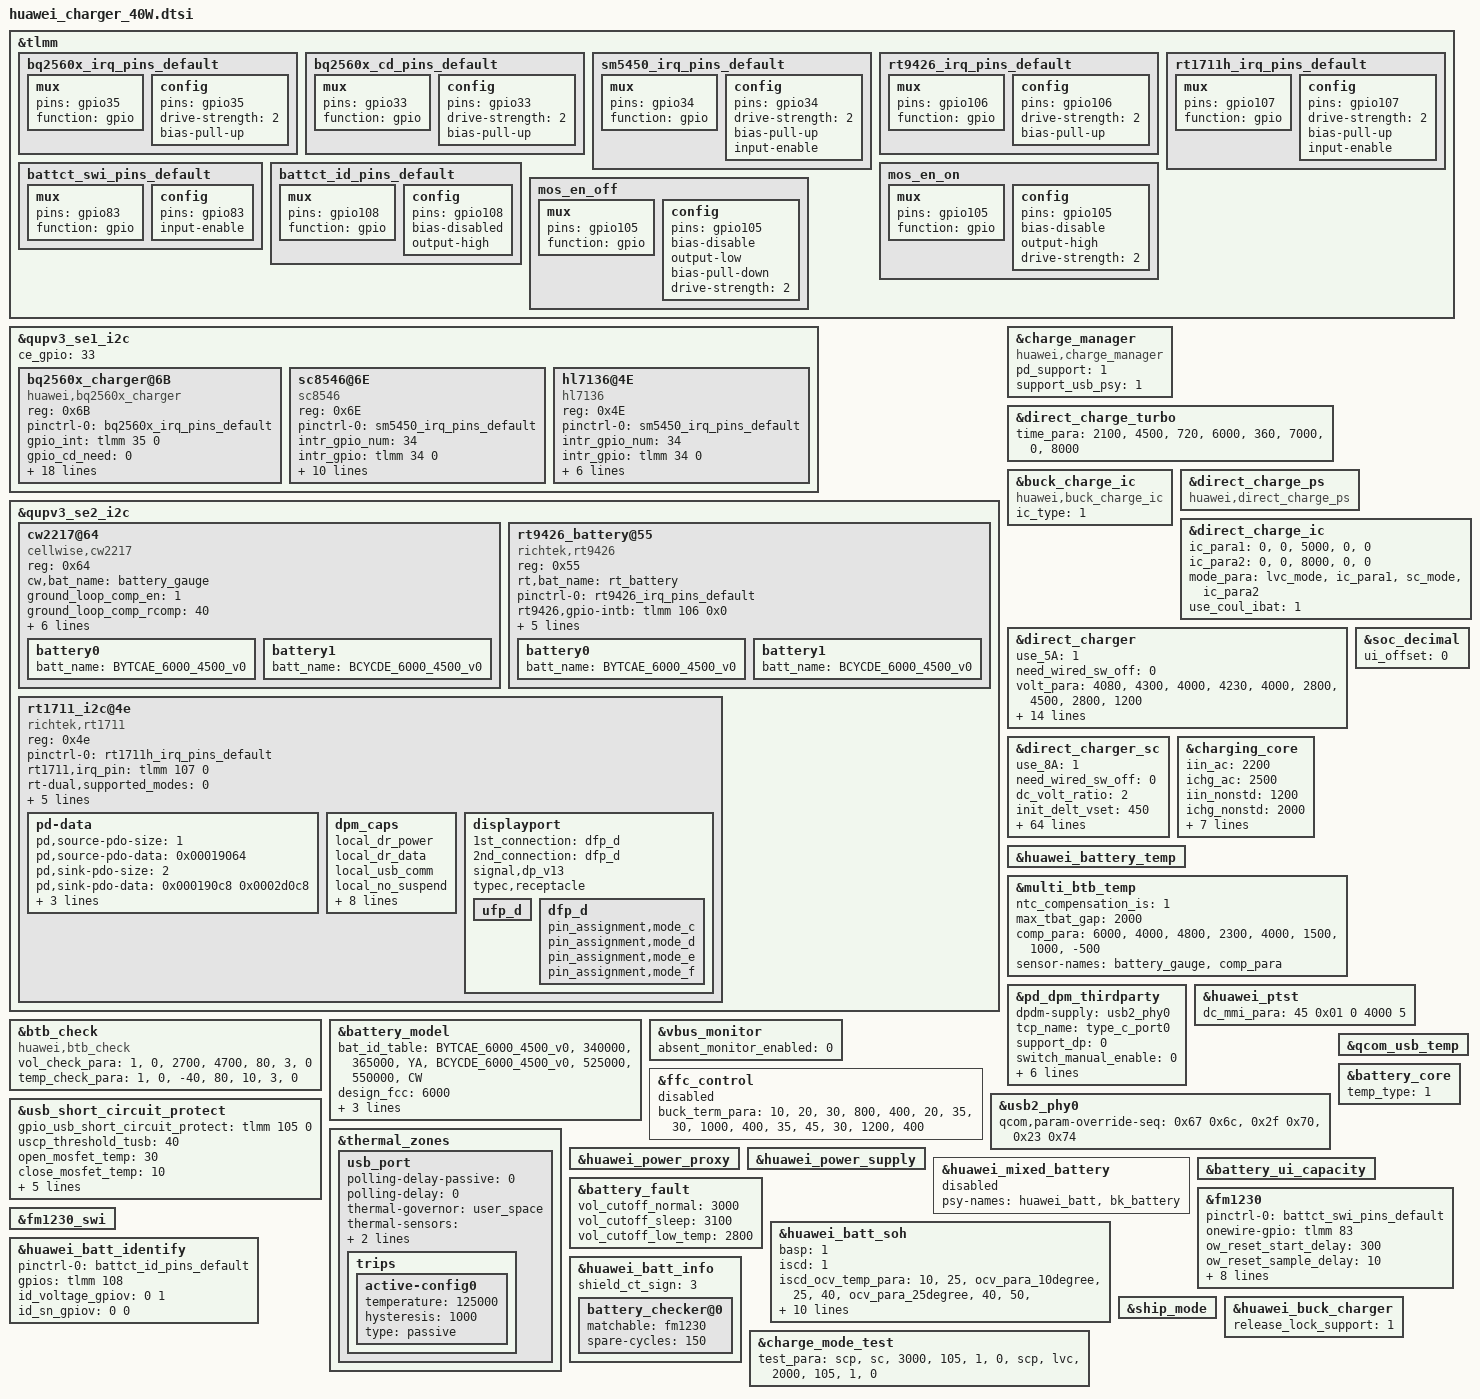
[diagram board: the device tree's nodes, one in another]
&tlmm {
	bq2560x_irq_pins_default: bq2560x_irq_pins_default {
		mux {
			pins = "gpio35";
			function = "gpio";
		};
		config {
			pins = "gpio35";
			drive-strength = <2>;
			bias-pull-up;
		};
	};

	bq2560x_cd_pins_default: bq2560x_cd_pins_default {
		mux {
			pins = "gpio33";
			function = "gpio";
		};
		config {
			pins = "gpio33";
			drive-strength = <2>;
			bias-pull-up;
		};
	};

	sm5450_irq_pins_default: sm5450_irq_pins_default {
		mux {
			pins = "gpio34";
			function = "gpio";
		};
		config {
			pins = "gpio34";
			drive-strength = <2>;
			bias-pull-up;
			input-enable;
		};
	};

	rt9426_irq_pins_default: rt9426_irq_pins_default {
		mux {
			pins = "gpio106";
			function = "gpio";
		};
		config {
			pins = "gpio106";
			drive-strength = <2>;
			bias-pull-up;
		};
	};

	rt1711h_irq_pins_default: rt1711h_irq_pins_default {
		mux {
			pins = "gpio107";
			function = "gpio";
		};
		config {
			pins = "gpio107";
			drive-strength = <2>;
			bias-pull-up;
			input-enable;
		};
	};

	battct_swi_pins_default: battct_swi_pins_default {
		mux {
			pins = "gpio83";
			function = "gpio";
		};
		config {
			pins = "gpio83";
			input-enable;
		};
	};

	battct_id_pins_default: battct_id_pins_default {
		mux {
			pins = "gpio108";
			function = "gpio";
		};
		config {
			pins = "gpio108";
			bias-disabled;
			output-high;
		};
	};

	mos_en_on: mos_en_on {
		mux {
			pins = "gpio105";
			function = "gpio";
		};

		config {
			pins = "gpio105";
			bias-disable;
			output-high;
			drive-strength = <2>; /* 2 MA */
		};
	};

	mos_en_off: mos_en_off {
		mux {
			pins = "gpio105";
			function = "gpio";
		};

		config {
			pins = "gpio105";
			bias-disable;
			output-low;
			bias-pull-down; /* PULL DOWN */
			drive-strength = <2>; /* 2 MA */
		};
	};
};

&qupv3_se1_i2c {
	status = "ok";

	/* auto_key_info @ name: ce_gpio type: uint32 default: 0 */
	ce_gpio = <33>;

	bq2560x_charger@6B{
		compatible = "huawei,bq2560x_charger";
		reg = <0x6B>;
		pinctrl-names = "bq2560x_irq_pins_default";
		pinctrl-0 = <&bq2560x_irq_pins_default>;
		gpio_int = <&tlmm 35 0>;
        gpio_cd_need = <0>;
		bat_comp = <80>;
		vclamp = <224>;
		rilim = <124>;
		adc_channel_iin = <5>;
		adc_channel_vbat_sys = <14>;
		fcp_support = <0>;
		need_check_sgm41511 = <0>;
		hiz_iin_limit = <1>;
		custom_cv = <4496>;
		charge-detect-enable;
		enable_redo_bc12;
		no_need_change_iterm;
		support_sc = <1>;
		ic_role = <1>;
		sc_max_input_current = <1200>;
		sc_max_charge_current  = <2100>;
		disable_batfet_rst_en = <1>; /* if support shipmode, need disable batfet_rst_en */
		shipmode_clear_hiz = <1>;
		status = "ok";
	};

	sc8546@6E {
		compatible = "sc8546";
		reg = <0x6E>;
		pinctrl-names = "default";
		pinctrl-0 = <&sm5450_irq_pins_default>;
		intr_gpio_num = <34>; /* direct defined GPIO num */
		intr_gpio = <&tlmm 34 0>;
		fcp_support = <1>;
		scp_support = <1>;
		sense_r_actual = <20>;
		i2c_recovery = <1>;
		i2c_recovery_addr = <0x6F>;
		switching_frequency = <850>;
		switching_frequency_shift = <1>;
		ic_role = <0>;
		sc_para =
			"default", "8000", "4800",
			"sc8546", "8000", "4800";
		status = "ok";
	};

	hl7136@4E {
		compatible = "hl7136";
		reg = <0x4E>;
		pinctrl-names = "default";
		pinctrl-0 = <&sm5450_irq_pins_default>;
		intr_gpio_num = <34>; /* direct defined GPIO num */
		intr_gpio = <&tlmm 34 0>;
		sense_r_actual = <20>;
		sense_r_config = <50>;
		fcp_support = <1>;
		scp_support = <1>;
		switching_frequency = <500>;
		ic_role = <0>;
		status = "ok";
	};
};

&qupv3_se2_i2c {
	status = "ok";
        cw2217@64 {
		compatible = "cellwise,cw2217";
		reg = <0x64>;
		cw,bat_name = "battery_gauge";
		status = "ok";
		ground_loop_comp_en = <1>;
		ground_loop_comp_rcomp = <40>;
		en_soft_reset = <1>;
		vbat_soc_table =
			"3813", "3836", "37",
			"3836", "3865", "43",
			"3865", "3905", "49",
			"3905", "3967", "55",
			"3967", "4032", "61",
			"4032", "4097", "67",
			"4097", "4167", "73",
			"4167", "4242", "79",
			"4242", "4315", "85",
			"4315", "4380", "91",
			"4380", "4445", "97";
		battery0{
			batt_name = "BYTCAE_6000_4500_v0";
			#include "../../../huawei_charger/cw2217_BYTCAE_6000mAh_4V50_BT339.dtsi"
		};
		battery1{
			batt_name = "BCYCDE_6000_4500_v0";
			#include "../../../huawei_charger/cw2217_BCYCDE_6000mAh_4V50_BT339.dtsi"
		};
	};

	rt9426_battery@55{
		reg = <0x55>;
		rt,bat_name = "rt_battery";
		compatible = "richtek,rt9426";
		pinctrl-names = "default";
		pinctrl-0 = <&rt9426_irq_pins_default>;
		rt9426,gpio-intb = <&tlmm 106 0x0>;
		need_reset_version = <9>;
		rt_config_ver = <12>; /* NOTICE: need increase 1 ,when  update batter model param */
		ntc_compensation_is = <1>;
		ground_loop_comp_en = <0>;
		ground_loop_comp_rcomp = <40>;
		status = "ok";
		battery0{
			batt_name = "BYTCAE_6000_4500_v0";
			#include "../../../huawei_charger/rt9426_BYTCAE_6100Ah_4V50_BT339.dtsi"
		};
		battery1{
			batt_name = "BCYCDE_6000_4500_v0";
			#include "../../../huawei_charger/rt9426_BCYCDE_6100Ah_4V50_BT339.dtsi"
		};
	};

	rt1711_i2c@4e {
		compatible = "richtek,rt1711";
		reg = <0x4e>;
		status = "ok";
		pinctrl-names = "default";
		pinctrl-0 = <&rt1711h_irq_pins_default>;
		rt1711,irq_pin = <&tlmm 107 0>;
		rt-dual,supported_modes = <0>; /* 0: dfp/ufp, 1: dfp, 2: ufp */
		rt-tcpc,name = "type_c_port0"; /* tcpc_device's name */
		rt-tcpc,role_def = <4>; /* 0: SNK Only, 1: SRC Only, 2: DRP, 3: Try.SRC, 4: Try.SNK */
		rt-tcpc,rp_level = <0>; /* 0: Default, 1: 1.5, 2: 3.0 */
		rt-tcpc,en_temporary_lock = <1>; /* add for qcom6225, attach_wake_lock */
		rt-tcpc,notifier_supply_num = <0>; /* the number of notifier supply */
		pd-data {
			pd,source-pdo-size = <1>;
			pd,source-pdo-data = <0x00019064>;  /*<0x019014>;*/

			pd,sink-pdo-size = <2>;
			pd,sink-pdo-data = <0x000190c8 0x0002d0c8> ;   /* 0x0002d0c8 : 9V, 2A */

			/*
			No DP
			pd,id-vdo-size = <3>;
			pd,id-vdo-data = <0x500029cf 0x0 0x00010000>;
			With DP
			pd,id-vdo-size = <4>;
			pd,id-vdo-data = <0xec0029cf 0x0 0x00010000 0x11000001>;
			*/

			pd,id-vdo-size = <4>;
			pd,id-vdo-data = <0xec0012d1 0x0 0x107e0000 0x11000001>;
		};
		dpm_caps {
			local_dr_power;
			local_dr_data;
			// local_ext_power;
			local_usb_comm;
			// local_usb_suspend;
			// local_high_cap;
			// local_give_back;
			local_no_suspend;
			local_vconn_supply;

			attemp_enter_dp_mode;
			attemp_discover_cable;
			attemp_discover_id;

			/* 0: disable, 1: prefer_snk, 2: prefer_src */
			pr_check = <0>;
			// pr_reject_as_source;
			// pr_reject_as_sink;
			pr_check_gp_source;
			// pr_check_gp_sink;

			/* 0: disable, 1: prefer_ufp, 2: prefer_dfp */
			dr_check = <0>;
			// dr_reject_as_dfp;
			// dr_reject_as_ufp;

			snk_prefer_low_voltage;
			// snk_ignore_mismatch_current;
		};
		displayport {
			/* connection type = "both", "ufp_d", "dfp_d" */
			1st_connection = "dfp_d";
			2nd_connection = "dfp_d";
			signal,dp_v13;
			//signal,dp_gen2;
			//usbr20_not_used;
			typec,receptacle;
			ufp_d {
				//pin_assignment,mode_a;
				//pin_assignment,mode_b;
				//pin_assignment,mode_c;
				//pin_assignment,mode_d;
				//pin_assignment,mode_e;
			};
			dfp_d {
				/* Only support mode C & D */
				//pin_assignment,mode_a;
				//pin_assignment,mode_b;
				pin_assignment,mode_c;
				pin_assignment,mode_d;
				pin_assignment,mode_e;
				pin_assignment,mode_f;
			};
		};
	};
};

&charge_manager {
	compatible = "huawei,charge_manager";
	pd_support = <1>;
	support_usb_psy = <1>;
	status = "ok";
};

&direct_charge_turbo {
	status = "ok";
	time_para =
		"2100", "4500",
		"720", "6000",
		"360", "7000",
		"0", "8000";
};

&buck_charge_ic {
	compatible = "huawei,buck_charge_ic";
	ic_type = <1>;
	status = "ok";
};

&direct_charge_ps {
	compatible = "huawei,direct_charge_ps";
	status = "ok";
};

&direct_charge_ic {
	/* ic_index  path_index  max_ibat  ibat_sample_point  vbat_sample_point */
	ic_para1 =
		"0", "0", "5000", "0", "0";
	ic_para2 =
		"0", "0", "8000", "0", "0";
	mode_para =
		"lvc_mode", "ic_para1",
		"sc_mode", "ic_para2";
	use_coul_ibat = <1>;
	status = "ok";
};

&direct_charger{
	use_5A = <1>;
	need_wired_sw_off = <0>;
	volt_para =
		"4080", "4300", "4000",
		"4230", "4000", "2800",
		"4500", "2800", "1200";
	vbat_comp_para =
		"default", "0", "0";
	compensate_r = <10>;
	cc_cable_detect_enable = <1>;
	vol_err_th = <250>;
	full_path_res_max = <280>;
	scp_work_on_charger = <1>;
	init_delt_vset = <400>;
	standard_cable_full_path_res_max = <330>;
	first_cc_stage_timer_in_min = <5>;
	stage_need_to_jump = "1";
	low_temp_hysteresis = <5>;
	temp_para =
		"-32767", "10", "0",
		"10", "45", "5000",
		"45", "32767", "0";
	rt_test_para =
		"2000", "105"; /* rt_curr_th rt_test_time */
	status = "ok";
};

&direct_charger_sc{
	use_8A = <1>;
	need_wired_sw_off = <0>;
	dc_volt_ratio = <2>;
	init_delt_vset = <450>;
	max_adaptor_vset = <10000>;
	init_adapter_vset = <8800>;
	vol_err_th = <500>;
	adaptor_leakage_current_th = <600>;
	vstep = <20>;
	min_dc_bat_vol = <3450>;
	max_dc_bat_vol = <4450>;
	max_current_for_none_standard_cable = <6000>;
	second_path_res_report_th = <180>;
	adaptor_antifake_check_enable = <1>;
	adaptor_antifake_key_index = <2>;
	second_resist_check_en = <0>;
	is_show_ico_first = <1>;
	ui_max_pwr = <40000>;
	product_max_pwr = <40000>;
	volt_para =
		"4150", "8000", "7200",
		"4250", "7200", "6000",
		"4530", "6000", "1000";
	volt_para1 =
		"4250", "8000", "7200",
		"4350", "7200", "6000",
		"4530", "6000", "1080";
	volt_para2 =
		"4250", "8000", "7200",
		"4350", "7200", "6000",
		"4530", "6000", "1200";
	time_para =
		"2100", "4500",
		"1200", "5000",
		"480", "5500",
		"300", "6000",
		"180", "7000",
		"0", "8000";
	bat_para =
		"default", "10", "20", "volt_para",
		"default", "20", "45", "volt_para1",
		"CAE", "10", "20", "volt_para",
		"CAE", "20", "35", "volt_para1",
		"CAE", "35", "45", "volt_para2",
		"CGL", "10", "20", "volt_para",
		"CGL", "20", "35", "volt_para1",
		"CGL", "35", "45", "volt_para2";
	vbat_comp_para =
		"default","0","0",
		"bq25970","10","10",
		"rt9759","15","15";
	vstep_para =
		"2000", "80";
	10v2p25a_cur_para =
		"-32767", "5500",  "2000",
		"5500",   "9000",  "2500",
		"9000",   "10000", "2250",
		"10000",  "10500", "2000",
		"10500",  "32767", "1500";
	10v2p25a_car_cur_para =
		"-32767", "5500",  "2000",
		"5500",   "9000",  "2500",
		"9000",   "10000", "2250",
		"10000",  "32767", "2000";
	adp_qtr_a_10v2p25a_cur_para =
		"-32767", "5500",  "4000",
		"5500",   "9000",  "2500",
		"9000",   "10000", "2250",
		"10000",  "10500", "2000",
		"10500",  "32767", "1500";
	adp_qtr_c_20v3a_cur_para =
		"-32767", "10300", "4000",
		"10300",  "32767", "3000";
	10v4a_cur_para =
		"-32767", "11000", "4000";
	compensate_r = <10>;
	all_stage_compensate_r_en = <1>;
	cc_cable_detect_enable = <1>;
	full_path_res_max = <450>;
	scp_work_on_charger = <1>;
	standard_cable_full_path_res_max = <450>;
	first_cc_stage_timer_in_min = <10>;
	stage_need_to_jump = "-1";
	low_temp_hysteresis = <5>;
	thre_para =
		"1650", "4465",
		"600", "4520";
	current_ratio =
		"3", "9", "50", "2", "-1",
		"3", "10", "50", "1", "8000",
		"0", "10", "50", "0", "0";
	vbat_error =
		"3", "220", "2", "-1",
		"3", "200", "1", "0";
	temp_para =
		"-32767", "10", "0",
		"10", "46", "12000",
		"46", "32767", "0";
	resist_para =
		"0", "260", "6000",
		"260", "450", "4000";
	std_resist_para =
		"0", "300", "0",
		"300", "450", "4000";
	second_resist_para =
		"0", "180", "0",
		"180", "450", "8000";
	ctc_second_resist_para =
		"0", "250", "0",
		"250", "450", "8000";
	rt_test_para =
		/* first:sc second:mainsc third:auxsc */
		"3000", "105",
		"3000", "105",
		"3000", "105";
	status = "ok";
};

&charging_core {
	iin_ac = <2200>;
	ichg_ac = <2500>;
	iin_nonstd = <1200>;
	ichg_nonstd = <2000>;
	iin_bc_usb = <1500>;
	ichg_bc_usb = <2000>;
	iterm = <180>;
	temp_para =
		"-32767", "1", "-1", "0", "4100", "0",
		"1", "5", "-1", "1800", "4500", "0",
		"5", "10", "-1", "1800", "4500", "3",
		"10", "45", "-1", "-1", "4500", "3",
		"45", "50", "-1", "2100", "4200", "3",
		"50", "32767", "-1", "0", "4100", "0";
	status = "ok";
};

&huawei_battery_temp {
	status = "ok";
};

&multi_btb_temp {
	status = "ok";
	ntc_compensation_is = <1>;
	max_tbat_gap = <2000>;
	comp_para =
		"6000", "4000",
		"4800", "2300",
		"4000", "1500",
		"1000", "-500";
	sensor-names =
		"battery_gauge", "comp_para";
};

&soc_decimal {
	ui_offset = <0>;
	status = "ok";
};

&pd_dpm_thirdparty {
	dpdm-supply = <&usb2_phy0>;
	tcp_name = "type_c_port0";
	support_dp = <0>;
	switch_manual_enable = <0>;
	abnormal_cc_detection = <1>;
	cc_dynamic_protect = <2>;
	moisture_detection_by_cc_enable = <1>;
	cc_moisture_status_report = <1>;
	cc_abnormal_dmd_report_enable = <1>;
	emark_detect_enable = <0>;
	status = "ok";
};

&btb_check {
	compatible = "huawei,btb_check";
	vol_check_para = "1", "0", "2700", "4700", "80", "3", "0";
	temp_check_para = "1", "0", "-40", "80", "10", "3", "0";
	status = "ok";
};

&huawei_ptst {
	dc_mmi_para = <45 0x01 0 4000 5>;
	status = "ok";
};

&battery_model {
	bat_id_table = "BYTCAE_6000_4500_v0", "340000", "365000", "YA",
					"BCYCDE_6000_4500_v0","525000","550000","CW";
	design_fcc = <6000>;
	support_iio = <1>;
	//io-channels = <&pmi632_vadc ADC_BAT_ID_PU2>;
	io-channel-names = "batt-id";
	id_adc_channel = <0>; /* useless but necessary for Qcom, set 0 as default */
	technology = <2>;
	status = "ok";
};

&vbus_monitor {
	status = "ok";
	absent_monitor_enabled = <0>;
};

&ffc_control {
	status = "disabled";
	buck_term_para =
		"10", "20", "30", "800", "400",
		"20", "35", "30", "1000", "400",
		"35", "45", "30", "1200", "400";
};

&usb2_phy0{
	qcom,param-override-seq = <0x67 0x6c>, //override_x0
				  <0x2f 0x70>, //override_x1
				  <0x23 0x74>; //override_x2
};

&qcom_usb_temp {
	status = "ok";
};

&usb_short_circuit_protect {
	gpio_usb_short_circuit_protect = <&tlmm 105 0>;
	uscp_threshold_tusb = <40>;
	open_mosfet_temp = <30>;
	close_mosfet_temp = <10>;
	open_hiz_temp = <30>;
	interval_switch_temp = <15>;
	use_pinctrl; /* for qcom6225, gpio use pinctrl */
	pinctrl-names = "mos_en_on", "mos_en_off";
	pinctrl-0 = <&mos_en_on>;
	pinctrl-1 = <&mos_en_off>;
	status = "ok";
};

&thermal_zones {
	usb_port {
		polling-delay-passive = <0>;
		polling-delay = <0>;
		thermal-governor = "user_space";
		thermal-sensors = <&pm6125_adc_tm_iio ADC_GPIO2_PU2>;
		wake-capable-sensor;
		trips {
			active-config0 {
				temperature = <125000>;
				hysteresis = <1000>;
				type = "passive";
			};
		};
	};
};

&huawei_power_proxy {
	status = "ok";
};

&huawei_power_supply {
	 status = "ok";
};

&huawei_mixed_battery {
	psy-names = "huawei_batt", "bk_battery";
	status = "disabled";
};

&battery_core {
	status = "ok";
	temp_type = <1>;
};

&battery_ui_capacity {
	status = "ok";
};

&battery_fault {
	vol_cutoff_normal = <3000>;
	vol_cutoff_sleep = <3100>;
	vol_cutoff_low_temp = <2800>;
	status = "ok";
};

&huawei_batt_soh {
	basp = <1>;
	iscd = <1>;
	iscd_ocv_temp_para =
		"10", "25", "ocv_para_10degree",
		"25", "40", "ocv_para_25degree",
		"40", "50", "ocv_para_40degree";
	ocv_para_10degree =
		"4454","100",
		"4389","95",
		"4331","90",
		"4274","85",
		"4213","80",
		"4153","75",
		"4096","70",
		"4045","65",
		"3986","60",
		"3928","55";
	ocv_para_25degree =
		"4453","100",
		"4391","95",
		"4334","90",
		"4277","85",
		"4215","80",
		"4155","75",
		"4098","70",
		"4048","65",
		"3996","60",
		"3939","55";
	ocv_para_40degree =
		"4448","100",
		"4386","95",
		"4328","90",
		"4272","85",
		"4210","80",
		"4150","75",
		"4094","70",
		"4044","65",
		"3993","60",
		"3939","55";
	status = "ok";
};

&fm1230 {
	pinctrl-names = "default";
	pinctrl-0 = <&battct_swi_pins_default>;
	onewire-gpio = <&tlmm 83 0>;
	ow_reset_start_delay = <300>;
	ow_reset_sample_delay = <10>;
	ow_reset_end_delay = <60>;
	ow_write_start_delay = <2>;
	ow_write_low_delay = <53>;
	ow_write_high_delay = <6>;
	ow_write_end_delay = <50>;
	ow_read_start_delay = <1>;
	ow_read_sample_delay = <7>;
	ow_read_end_delay = <100>;
	status = "ok";
};

&fm1230_swi {
	status = "ok";
};

&huawei_batt_identify {
	pinctrl-names = "default";
	pinctrl-0 = <&battct_id_pins_default>;
	gpios = <&tlmm 108 0>;
	id_voltage_gpiov = <0 1>;
	id_sn_gpiov = <0 0>;
	status = "ok";
};

&huawei_batt_info {
	status = "ok";
	shield_ct_sign = <3>;
	battery_checker@0 {
		matchable = <&fm1230>;
		spare-cycles = <150>;
		status = "ok";
	};
};

&ship_mode {
	status = "ok";
};

&huawei_buck_charger {
	release_lock_support = <1>;
};

&charge_mode_test {
	/* protocol  mode  ibat_th  time  early_termination  force_test */
	test_para =
		"scp", "sc", "3000", "105", "1", "0",
		"scp", "lvc", "2000", "105", "1", "0";
	status = "ok";
};
